# PIC32MK0128MCA048 register map
Vendor: Microchip
Registers are 32-bit, read-write, reset 0x0 unless marked. A register's access mark holds for its fields unless they carry their own. Addresses are absolute, and some are shared; only a register's first bit layout is shown; [hi:lo] are bit positions; {n}, {i} and the like mark numbered series.

## CFG
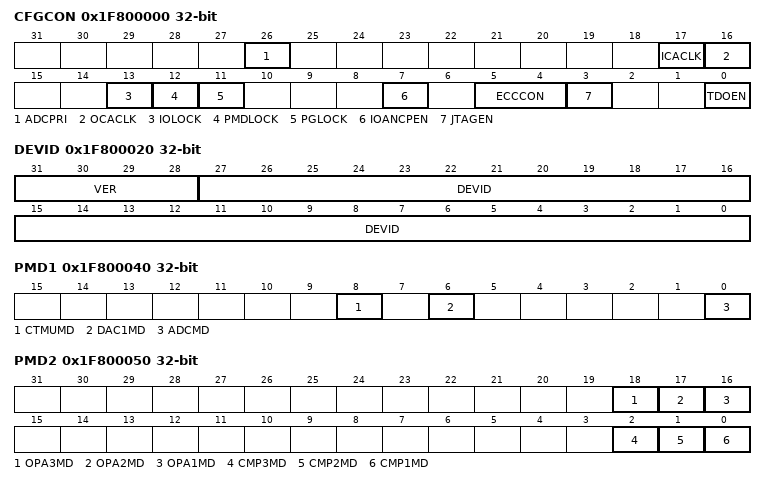
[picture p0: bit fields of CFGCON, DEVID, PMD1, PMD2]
0x1F800000 CFGCON reset not defined — (power-on value -----0--------00--000---0-xx0--1)
  [26] ADCPRI
  [17] ICACLK
  [16] OCACLK
  [13] IOLOCK
  [12] PMDLOCK
  [11] PGLOCK
  [7] IOANCPEN
  [5:4] ECCCON — Flash ECC Configuration Bits
  [3] JTAGEN
  [0] TDOEN
0x1F800020 DEVID reset not defined — (power-on value 0000xxxxxxxxxxxxxxxxxxxxxxxxxxxx)
  [31:28] VER ro, [27:0] DEVID
0x1F800030 SYSKEY
0x1F800040 PMD1 reset not defined — (power-on value -----------------------x-x-----0)
  [8] CTMUMD, [6] DAC1MD, [0] ADCMD
0x1F800050 PMD2 reset not defined — (power-on value -------------xxx-------------x00)
  [18] OPA3MD, [17] OPA2MD, [16] OPA1MD, [2] CMP3MD, [1] CMP2MD, [0] CMP1MD
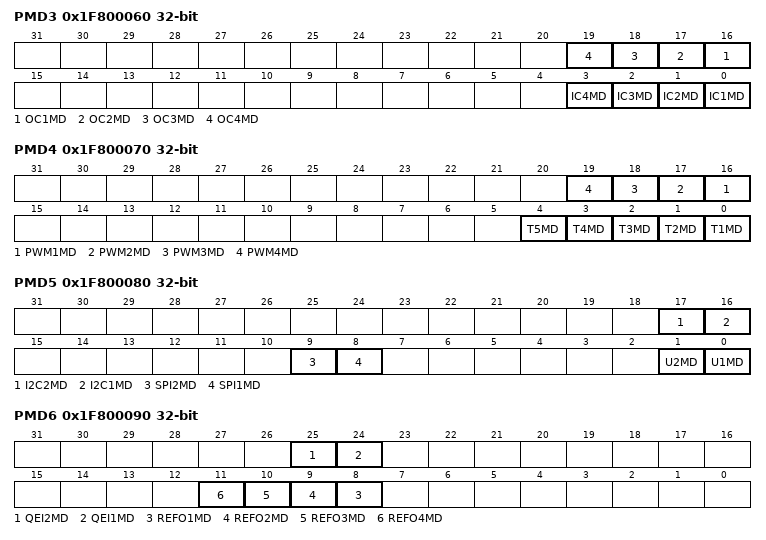
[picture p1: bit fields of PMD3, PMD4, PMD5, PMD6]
0x1F800060 PMD3
  [n+15] OC{n}MD (n=1..4), [n-1] IC{n}MD (n=1..4)
0x1F800070 PMD4 reset not defined — (power-on value ------------xxxx-----------11111)
  [n+15] PWM{n}MD (n=1..4), [n-1] T{n}MD (n=1..5)
0x1F800080 PMD5
  [17] I2C2MD, [16] I2C1MD, [9] SPI2MD, [8] SPI1MD, [1] U2MD, [0] U1MD
0x1F800090 PMD6 reset not defined — (power-on value ------xx------------0000-------0)
  [25] QEI2MD, [24] QEI1MD, [n+7] REFO{n}MD (n=1..4)
0x1F8000A0 PMD7
  [4] DMAMD
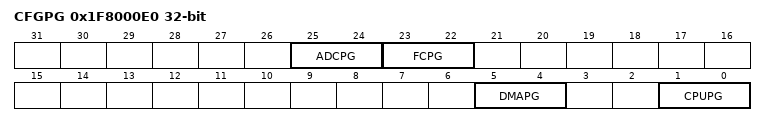
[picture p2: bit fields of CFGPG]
0x1F8000E0 CFGPG
  [25:24] ADCPG, [23:22] FCPG, [5:4] DMAPG, [1:0] CPUPG

## PCACHE
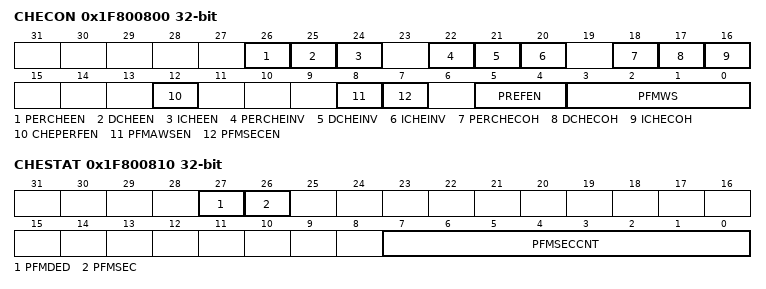
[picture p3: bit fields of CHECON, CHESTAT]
0x1F800800 CHECON reset not defined — (power-on value -----111-000-000---0---1x-00xxxx)
  [26] PERCHEEN, [25] DCHEEN, [24] ICHEEN, [22] PERCHEINV, [21] DCHEINV, [20] ICHEINV, [18] PERCHECOH, [17] DCHECOH, [16] ICHECOH, [12] CHEPERFEN, [8] PFMAWSEN, [7] PFMSECEN, [5:4] PREFEN, [3:0] PFMWS
0x1F800810 CHESTAT reset not defined — (power-on value ----xx------------------xxxxxxxx)
  [27] PFMDED, [26] PFMSEC, [7:0] PFMSECCNT
0x1F800820 CHEHIT reset not defined — (power-on value xxxxxxxxxxxxxxxxxxxxxxxxxxxxxxxx)
  [31:0] CHEHIT — (can only be cleared)
0x1F800830 CHEMIS reset not defined — (power-on value xxxxxxxxxxxxxxxxxxxxxxxxxxxxxxxx)
  [31:0] CHEMIS — (can only be cleared)

## NVM
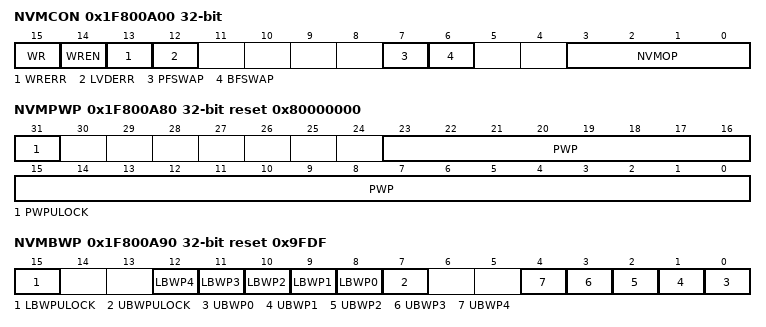
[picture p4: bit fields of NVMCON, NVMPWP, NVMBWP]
0x1F800A00 NVMCON reset not defined — (power-on value ----------------0000----0x--0000)
  [15] WR, [14] WREN, [13] WRERR, [12] LVDERR, [7] PFSWAP, [6] BFSWAP, [3:0] NVMOP
0x1F800A10 NVMKEY wo
0x1F800A20 NVMADDR
{0x1F800A30+0x10*i} NVMDATA{i} (i=0..3)
0x1F800A70 NVMSRCADDR
0x1F800A80 NVMPWP reset 0x80000000
  [31] PWPULOCK, [23:0] PWP
0x1F800A90 NVMBWP reset 0x9FDF
  [15] LBWPULOCK, [n+8] LBWP{n} (n=0..4), [7] UBWPULOCK, [n] UBWP{n} (n=0..4)
0x1F800AA0 NVMCON2 reset not defined — (power-on value xxxx-------xxxxxx-xx--xx00------)
  [7:6] SWAPLOCK

## WDT
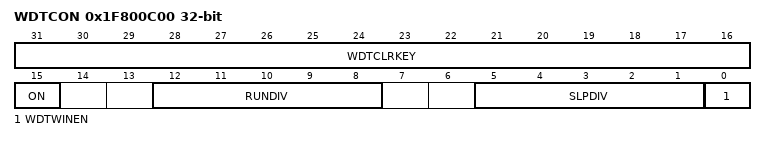
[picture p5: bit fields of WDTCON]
0x1F800C00 WDTCON reset not defined — (power-on value 0000000000000000x--xxxxx--xxxxx0)
  [31:16] WDTCLRKEY wo, [15] ON, [12:8] RUNDIV ro, [5:1] SLPDIV ro, [0] WDTWINEN

## DMT
0x1F800E00 DMTCON
  [15] ON
0x1F800E10 DMTPRECLR
  [15:8] STEP1
0x1F800E20 DMTCLR
  [7:0] STEP2
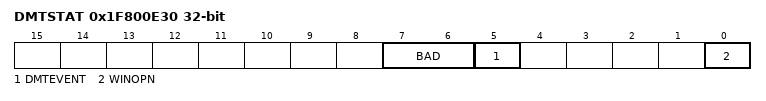
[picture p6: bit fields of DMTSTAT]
0x1F800E30 DMTSTAT ro
  [7:6] BAD, [5] DMTEVENT, [0] WINOPN
0x1F800E40 DMTCNT ro
  [31:0] COUNTER
0x1F800E60 DMTPSCNT ro reset not defined — (power-on value xxxxxxxxxxxxxxxxxxxxxxxxxxxxxxxx)
  [31:0] PSCNT
0x1F800E70 DMTPSINTV ro reset not defined — (power-on value xxxxxxxxxxxxxxxxxxxxxxxxxxxxxxxx)
  [31:0] PSINTV

## icd_jtag_bvci_upb
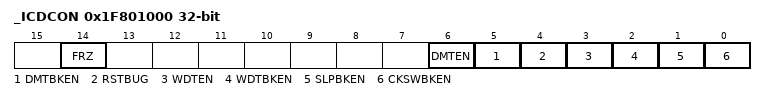
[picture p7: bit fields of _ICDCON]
0x1F801000 _ICDCON
  [14] FRZ, [6] DMTEN, [5] DMTBKEN, [4] RSTBUG, [3] WDTEN, [2] WDTBKEN, [1] SLPBKEN, [0] CKSWBKEN

## _DDPSTAT
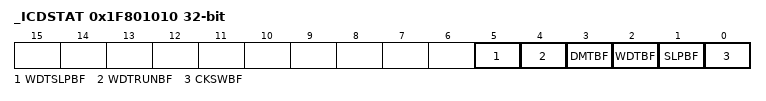
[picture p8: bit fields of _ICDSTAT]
0x1F801010 _ICDSTAT
  [5] WDTSLPBF, [4] WDTRUNBF, [3] DMTBF, [2] WDTBF, [1] SLPBF, [0] CKSWBF

## CRU
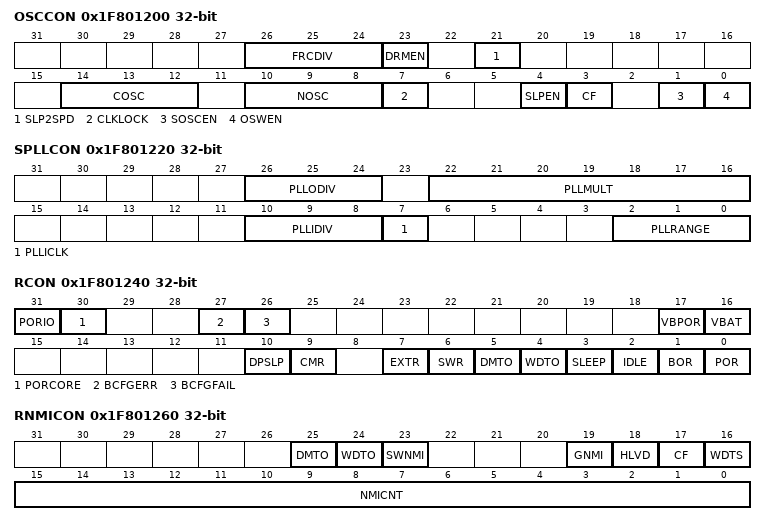
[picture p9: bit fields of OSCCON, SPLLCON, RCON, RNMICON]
0x1F801200 OSCCON reset not defined — (power-on value -----0000-x------000-xxx0--00-x0)
  [26:24] FRCDIV, [23] DRMEN, [21] SLP2SPD, [14:12] COSC ro, [10:8] NOSC, [7] CLKLOCK, [4] SLPEN, [3] CF, [1] SOSCEN, [0] OSWEN
0x1F801210 OSCTUN
  [5:0] TUN
0x1F801220 SPLLCON reset not defined — (power-on value -----001-xxxxxxx-----xxx0----xxx)
  [26:24] PLLODIV, [22:16] PLLMULT, [10:8] PLLIDIV, [7] PLLICLK, [2:0] PLLRANGE
0x1F801240 RCON reset not defined — (power-on value 00--xx---------------x0-00000011)
  [31] PORIO
  [30] PORCORE
  [27] BCFGERR — Primary Configuration Registers Error Flag bit
    1=An error occurred during a read of the primary configuration registers; 0=No error occurred during a read of the primary configuration registers
  [26] BCFGFAIL — Primary/Secondary Configuration Registers Error Flag bit
    1=An error occurred during a read of the primary and alternate configuration registers; 0=No error occurred during a read of the primary and alternate configuration registers
  [17] VBPOR
  [16] VBAT
  [10] DPSLP
  [9] CMR
  [7] EXTR
  [6] SWR
  [5] DMTO
  [4] WDTO
  [3] SLEEP
  [2] IDLE
  [1] BOR
  [0] POR
0x1F801250 RSWRST wo
  [0] SWRST
0x1F801260 RNMICON reset not defined — (power-on value ------0x0---0-000000000000000000)
  [25] DMTO, [24] WDTO, [23] SWNMI, [19] GNMI, [18] HLVD, [17] CF, [16] WDTS, [15:0] NMICNT
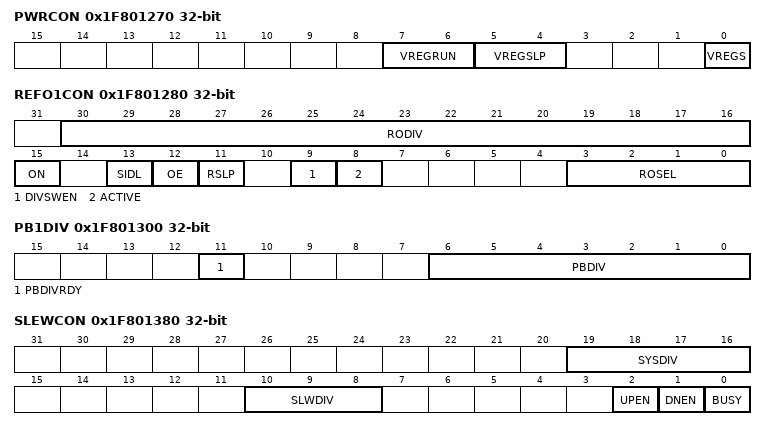
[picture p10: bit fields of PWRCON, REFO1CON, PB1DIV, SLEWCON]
0x1F801270 PWRCON reset not defined — (power-on value ------------------------xxxx---0)
  [7:6] VREGRUN, [5:4] VREGSLP, [0] VREGS
0x1F801280 REFO1CON
  [30:16] RODIV, [15] ON, [13] SIDL, [12] OE, [11] RSLP, [9] DIVSWEN, [8] ACTIVE ro, [3:0] ROSEL
0x1F801290 REFO1TRIM
  [31:23] ROTRIM
0x1F801300 PB1DIV reset not defined — (power-on value --------------------1----xxxxxxx)
  [11] PBDIVRDY ro, [6:0] PBDIV
0x1F801380 SLEWCON
  [19:16] SYSDIV, [10:8] SLWDIV, [2] UPEN, [1] DNEN, [0] BUSY
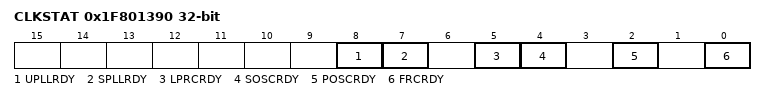
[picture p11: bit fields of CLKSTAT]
0x1F801390 CLKSTAT ro
  [8] UPLLRDY, [7] SPLLRDY, [5] LPRCRDY, [4] SOSCRDY, [2] POSCRDY, [0] FRCRDY
